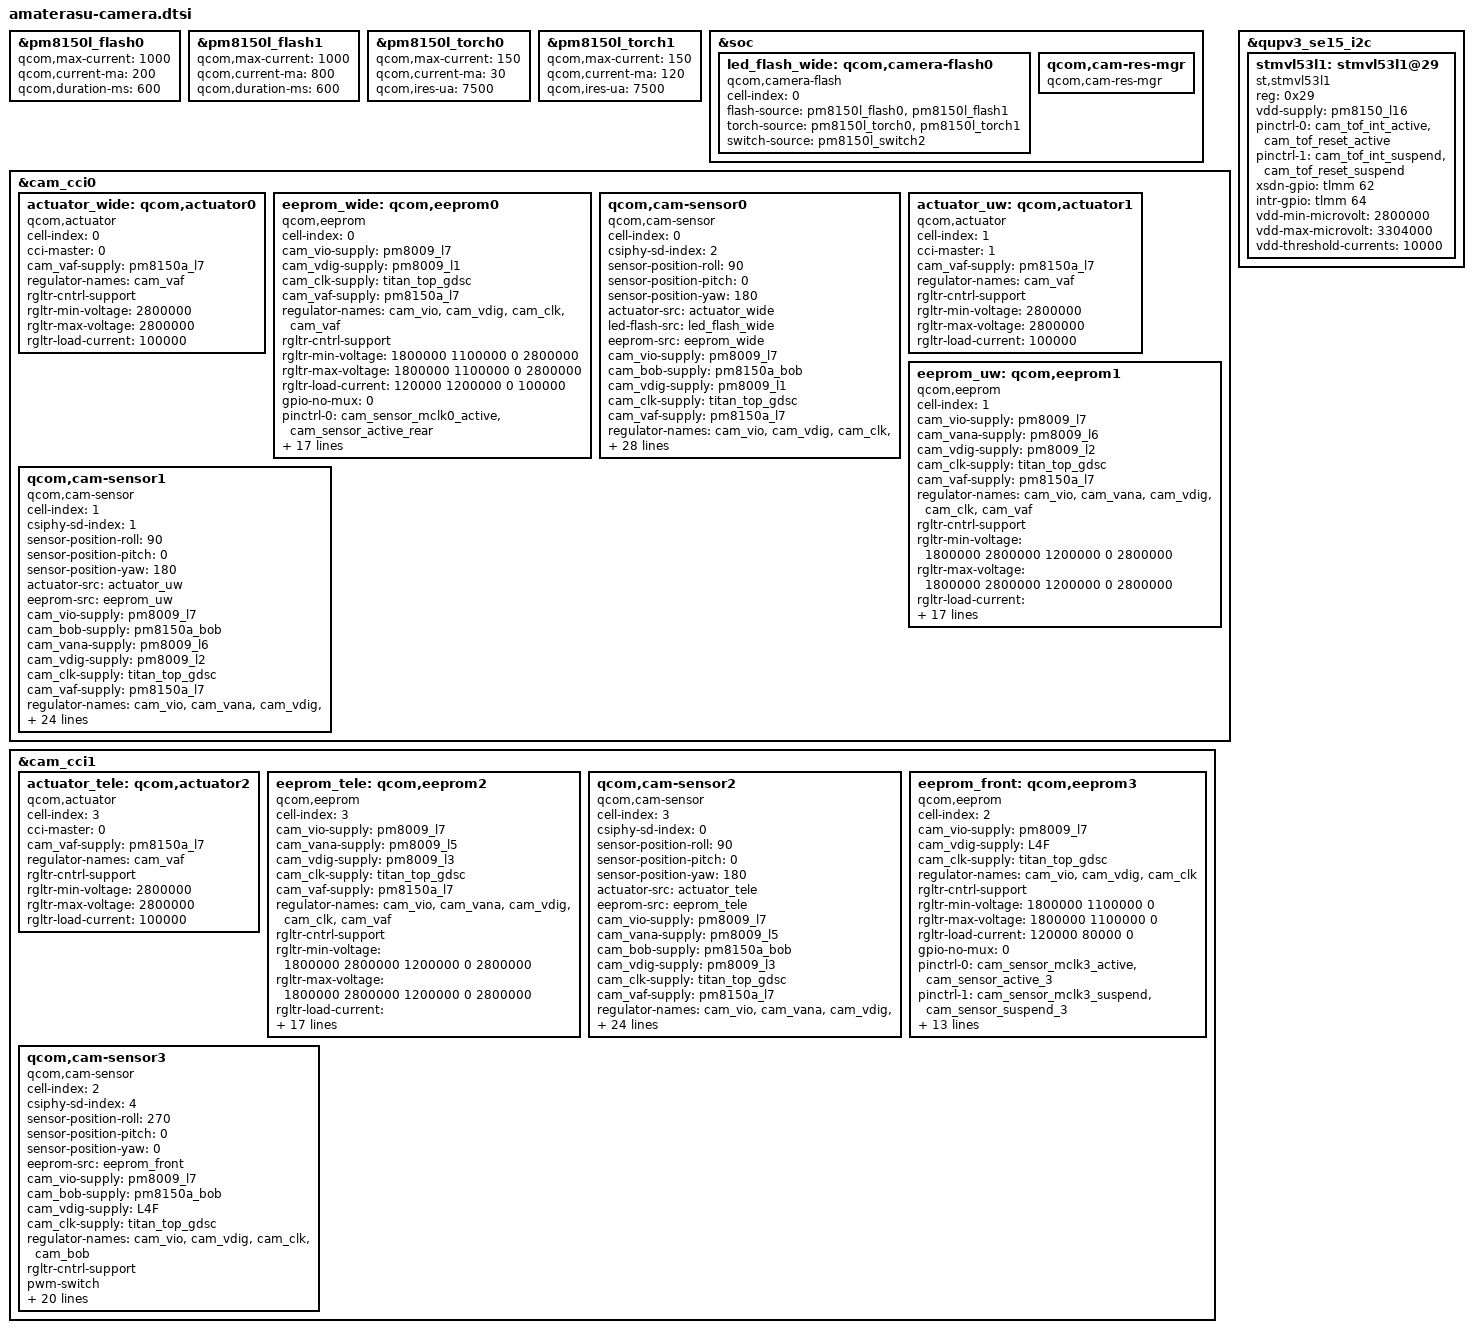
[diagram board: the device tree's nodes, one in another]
/*
 * FCNT arrows 5G (F-51A) - Camera: CCI sensors/actuators/EEPROMs, flash LEDs, resource manager and VL53L1 ToF.
 *
 * Reconstructed from the FCNT stock dtbo (kona FFRD REV7 SKU3); FFRD is
 * derived from the CLO kona QRD board files.
 */

&pm8150l_flash0 {
	qcom,max-current = <1000>;
	qcom,current-ma = <200>;
	qcom,duration-ms = <600>;
};

&pm8150l_flash1 {
	qcom,max-current = <1000>;
	qcom,current-ma = <800>;
	qcom,duration-ms = <600>;
};

&pm8150l_torch0 {
	qcom,max-current = <150>;
	qcom,current-ma = <30>;
	qcom,ires-ua = <7500>;
};

&pm8150l_torch1 {
	qcom,max-current = <150>;
	qcom,current-ma = <120>;
	qcom,ires-ua = <7500>;
};

&soc {
	led_flash_wide: qcom,camera-flash0 {
		cell-index = <0>;
		compatible = "qcom,camera-flash";
		flash-source = <&pm8150l_flash0 &pm8150l_flash1>;
		torch-source = <&pm8150l_torch0 &pm8150l_torch1>;
		switch-source = <&pm8150l_switch2>;
		status = "ok";
	};

	qcom,cam-res-mgr {
		compatible = "qcom,cam-res-mgr";
		status = "ok";
	};
};

&cam_cci0 {
	actuator_wide: qcom,actuator0 {
		cell-index = <0>;
		compatible = "qcom,actuator";
		cci-master = <0>;
		cam_vaf-supply = <&pm8150a_l7>;
		regulator-names = "cam_vaf";
		rgltr-cntrl-support;
		rgltr-min-voltage = <2800000>;
		rgltr-max-voltage = <2800000>;
		rgltr-load-current = <100000>;
	};

	eeprom_wide: qcom,eeprom0 {
		cell-index = <0>;
		compatible = "qcom,eeprom";
		cam_vio-supply = <&pm8009_l7>;
		cam_vdig-supply = <&pm8009_l1>;
		cam_clk-supply = <&titan_top_gdsc>;
		cam_vaf-supply = <&pm8150a_l7>;
		regulator-names = "cam_vio", "cam_vdig", "cam_clk", "cam_vaf";
		rgltr-cntrl-support;
		rgltr-min-voltage = <1800000 1100000 0 2800000>;
		rgltr-max-voltage = <1800000 1100000 0 2800000>;
		rgltr-load-current = <120000 1200000 0 100000>;
		gpio-no-mux = <0>;
		pinctrl-names = "cam_default", "cam_suspend";
		pinctrl-0 = <&cam_sensor_mclk0_active &cam_sensor_active_rear>;
		pinctrl-1 = <&cam_sensor_mclk0_suspend &cam_sensor_suspend_rear>;
		gpios = <&tlmm 94 0 &tlmm 93 0 &pm8009_gpios 2 0 &pm8009_gpios 3 0>;
		gpio-reset = <1>;
		gpio-custom1 = <2>;
		gpio-custom2 = <3>;
		gpio-req-tbl-num = <0 1 2 3>;
		gpio-req-tbl-flags = <0x1 0x0 0x0 0x0>;
		gpio-req-tbl-label = "CAMIF_MCLK0", "CAM_RESET", "CAM_VANA", "CAM_VANA2";
		sensor-position = <0>;
		sensor-mode = <0>;
		cci-master = <0>;
		status = "ok";
		clocks = <&clock_camcc 0x49>;
		clock-names = "cam_clk";
		clock-cntl-level = "turbo";
		clock-rates = <0x16e3600>;
	};

	qcom,cam-sensor0 {
		cell-index = <0>;
		compatible = "qcom,cam-sensor";
		csiphy-sd-index = <2>;
		sensor-position-roll = <90>;
		sensor-position-pitch = <0>;
		sensor-position-yaw = <180>;
		actuator-src = <&actuator_wide>;
		led-flash-src = <&led_flash_wide>;
		eeprom-src = <&eeprom_wide>;
		cam_vio-supply = <&pm8009_l7>;
		cam_bob-supply = <&pm8150a_bob>;
		cam_vdig-supply = <&pm8009_l1>;
		cam_clk-supply = <&titan_top_gdsc>;
		cam_vaf-supply = <&pm8150a_l7>;
		regulator-names = "cam_vio", "cam_vdig", "cam_clk", "cam_bob", "cam_vaf";
		rgltr-cntrl-support;
		pwm-switch;
		rgltr-min-voltage = <1800000 1100000 0 3008000 2800000>;
		rgltr-max-voltage = <1800000 1100000 0 3960000 2800000>;
		rgltr-load-current = <120000 1200000 0 2000000 100000>;
		gpio-no-mux = <0>;
		pinctrl-names = "cam_default", "cam_suspend";
		pinctrl-0 = <&cam_sensor_mclk0_active &cam_sensor_active_rear>;
		pinctrl-1 = <&cam_sensor_mclk0_suspend &cam_sensor_suspend_rear>;
		gpios = <&tlmm 94 0 &tlmm 93 0 &pm8009_gpios 2 0 &pm8009_gpios 3 0>;
		gpio-reset = <1>;
		gpio-custom1 = <2>;
		gpio-custom2 = <3>;
		gpio-req-tbl-num = <0 1 2 3>;
		gpio-req-tbl-flags = <0x1 0x0 0x0 0x0>;
		gpio-req-tbl-label = "CAMIF_MCLK0", "CAM_RESET", "CAM_VANA", "CAM_VANA2";
		sensor-mode = <0>;
		cci-master = <0>;
		status = "ok";
		clocks = <&clock_camcc 0x49>;
		clock-names = "cam_clk";
		clock-cntl-level = "turbo";
		clock-rates = <0x16e3600>;
	};

	actuator_uw: qcom,actuator1 {
		cell-index = <1>;
		compatible = "qcom,actuator";
		cci-master = <1>;
		cam_vaf-supply = <&pm8150a_l7>;
		regulator-names = "cam_vaf";
		rgltr-cntrl-support;
		rgltr-min-voltage = <2800000>;
		rgltr-max-voltage = <2800000>;
		rgltr-load-current = <100000>;
	};

	eeprom_uw: qcom,eeprom1 {
		cell-index = <1>;
		compatible = "qcom,eeprom";
		cam_vio-supply = <&pm8009_l7>;
		cam_vana-supply = <&pm8009_l6>;
		cam_vdig-supply = <&pm8009_l2>;
		cam_clk-supply = <&titan_top_gdsc>;
		cam_vaf-supply = <&pm8150a_l7>;
		regulator-names = "cam_vio", "cam_vana", "cam_vdig", "cam_clk", "cam_vaf";
		rgltr-cntrl-support;
		rgltr-min-voltage = <1800000 2800000 1200000 0 2800000>;
		rgltr-max-voltage = <1800000 2800000 1200000 0 2800000>;
		rgltr-load-current = <120000 80000 1200000 0 100000>;
		gpio-no-mux = <0>;
		pinctrl-names = "cam_default", "cam_suspend";
		pinctrl-0 = <&cam_sensor_mclk1_active &cam_sensor_active_rear_aux>;
		pinctrl-1 = <&cam_sensor_mclk1_suspend &cam_sensor_suspend_rear_aux>;
		gpios = <&tlmm 95 0 &tlmm 92 0>;
		gpio-reset = <1>;
		gpio-req-tbl-num = <0 1>;
		gpio-req-tbl-flags = <0x1 0x0>;
		gpio-req-tbl-label = "CAMIF_MCLK1", "CAM_RESET";
		sensor-position = <0>;
		sensor-mode = <0>;
		cci-master = <1>;
		status = "ok";
		clocks = <&clock_camcc 0x4b>;
		clock-names = "cam_clk";
		clock-cntl-level = "turbo";
		clock-rates = <0x16e3600>;
	};

	qcom,cam-sensor1 {
		cell-index = <1>;
		compatible = "qcom,cam-sensor";
		csiphy-sd-index = <1>;
		sensor-position-roll = <90>;
		sensor-position-pitch = <0>;
		sensor-position-yaw = <180>;
		actuator-src = <&actuator_uw>;
		eeprom-src = <&eeprom_uw>;
		cam_vio-supply = <&pm8009_l7>;
		cam_bob-supply = <&pm8150a_bob>;
		cam_vana-supply = <&pm8009_l6>;
		cam_vdig-supply = <&pm8009_l2>;
		cam_clk-supply = <&titan_top_gdsc>;
		cam_vaf-supply = <&pm8150a_l7>;
		regulator-names = "cam_vio", "cam_vana", "cam_vdig", "cam_clk", "cam_bob", "cam_vaf";
		rgltr-cntrl-support;
		pwm-switch;
		rgltr-min-voltage = <1800000 2800000 1200000 0 3008000 2800000>;
		rgltr-max-voltage = <1800000 2800000 1200000 0 3960000 2800000>;
		rgltr-load-current = <120000 80000 1200000 0 2000000 100000>;
		gpio-no-mux = <0>;
		pinctrl-names = "cam_default", "cam_suspend";
		pinctrl-0 = <&cam_sensor_mclk1_active &cam_sensor_active_rear_aux>;
		pinctrl-1 = <&cam_sensor_mclk1_suspend &cam_sensor_suspend_rear_aux>;
		gpios = <&tlmm 95 0 &tlmm 92 0>;
		gpio-reset = <1>;
		gpio-req-tbl-num = <0 1>;
		gpio-req-tbl-flags = <0x1 0x0>;
		gpio-req-tbl-label = "CAMIF_MCLK1", "CAM_RESET";
		sensor-mode = <0>;
		cci-master = <1>;
		status = "ok";
		clocks = <&clock_camcc 0x4b>;
		clock-names = "cam_clk";
		clock-cntl-level = "turbo";
		clock-rates = <0x16e3600>;
	};
};

&cam_cci1 {
	actuator_tele: qcom,actuator2 {
		cell-index = <3>;
		compatible = "qcom,actuator";
		cci-master = <0>;
		cam_vaf-supply = <&pm8150a_l7>;
		regulator-names = "cam_vaf";
		rgltr-cntrl-support;
		rgltr-min-voltage = <2800000>;
		rgltr-max-voltage = <2800000>;
		rgltr-load-current = <100000>;
	};

	eeprom_tele: qcom,eeprom2 {
		cell-index = <3>;
		compatible = "qcom,eeprom";
		cam_vio-supply = <&pm8009_l7>;
		cam_vana-supply = <&pm8009_l5>;
		cam_vdig-supply = <&pm8009_l3>;
		cam_clk-supply = <&titan_top_gdsc>;
		cam_vaf-supply = <&pm8150a_l7>;
		regulator-names = "cam_vio", "cam_vana", "cam_vdig", "cam_clk", "cam_vaf";
		rgltr-cntrl-support;
		rgltr-min-voltage = <1800000 2800000 1200000 0 2800000>;
		rgltr-max-voltage = <1800000 2800000 1200000 0 2800000>;
		rgltr-load-current = <120000 80000 1200000 0 100000>;
		gpio-no-mux = <0>;
		pinctrl-names = "cam_default", "cam_suspend";
		pinctrl-0 = <&cam_sensor_mclk2_active &cam_sensor_active_rst2>;
		pinctrl-1 = <&cam_sensor_mclk2_suspend &cam_sensor_suspend_rst2>;
		gpios = <&tlmm 96 0 &tlmm 78 0>;
		gpio-reset = <1>;
		gpio-req-tbl-num = <0 1>;
		gpio-req-tbl-flags = <0x1 0x0>;
		gpio-req-tbl-label = "CAMIF_MCLK2", "CAM_RESET";
		sensor-position = <0>;
		sensor-mode = <0>;
		cci-master = <0>;
		status = "ok";
		clocks = <&clock_camcc 0x4d>;
		clock-names = "cam_clk";
		clock-cntl-level = "turbo";
		clock-rates = <0x16e3600>;
	};

	qcom,cam-sensor2 {
		cell-index = <3>;
		compatible = "qcom,cam-sensor";
		csiphy-sd-index = <0>;
		sensor-position-roll = <90>;
		sensor-position-pitch = <0>;
		sensor-position-yaw = <180>;
		actuator-src = <&actuator_tele>;
		eeprom-src = <&eeprom_tele>;
		cam_vio-supply = <&pm8009_l7>;
		cam_vana-supply = <&pm8009_l5>;
		cam_bob-supply = <&pm8150a_bob>;
		cam_vdig-supply = <&pm8009_l3>;
		cam_clk-supply = <&titan_top_gdsc>;
		cam_vaf-supply = <&pm8150a_l7>;
		regulator-names = "cam_vio", "cam_vana", "cam_vdig", "cam_clk", "cam_bob", "cam_vaf";
		rgltr-cntrl-support;
		pwm-switch;
		rgltr-min-voltage = <1800000 2800000 1200000 0 3008000 2800000>;
		rgltr-max-voltage = <1800000 2800000 1200000 0 3960000 2800000>;
		rgltr-load-current = <120000 80000 1200000 0 2000000 100000>;
		gpio-no-mux = <0>;
		pinctrl-names = "cam_default", "cam_suspend";
		pinctrl-0 = <&cam_sensor_mclk2_active &cam_sensor_active_rst2>;
		pinctrl-1 = <&cam_sensor_mclk2_suspend &cam_sensor_suspend_rst2>;
		gpios = <&tlmm 96 0 &tlmm 78 0>;
		gpio-reset = <1>;
		gpio-req-tbl-num = <0 1>;
		gpio-req-tbl-flags = <0x1 0x0>;
		gpio-req-tbl-label = "CAMIF_MCLK2", "CAM_RESET";
		sensor-mode = <0>;
		cci-master = <0>;
		status = "ok";
		clocks = <&clock_camcc 0x4d>;
		clock-names = "cam_clk";
		clock-cntl-level = "turbo";
		clock-rates = <0x16e3600>;
	};

	eeprom_front: qcom,eeprom3 {
		cell-index = <2>;
		compatible = "qcom,eeprom";
		cam_vio-supply = <&pm8009_l7>;
		cam_vdig-supply = <&L4F>;
		cam_clk-supply = <&titan_top_gdsc>;
		regulator-names = "cam_vio", "cam_vdig", "cam_clk";
		rgltr-cntrl-support;
		rgltr-min-voltage = <1800000 1100000 0>;
		rgltr-max-voltage = <1800000 1100000 0>;
		rgltr-load-current = <120000 80000 0>;
		gpio-no-mux = <0>;
		pinctrl-names = "cam_default", "cam_suspend";
		pinctrl-0 = <&cam_sensor_mclk3_active &cam_sensor_active_3>;
		pinctrl-1 = <&cam_sensor_mclk3_suspend &cam_sensor_suspend_3>;
		gpios = <&tlmm 97 0 &tlmm 109 0 &pm8009_gpios 4 0>;
		gpio-reset = <1>;
		gpio-custom1 = <2>;
		gpio-req-tbl-num = <0 1 2>;
		gpio-req-tbl-flags = <0x1 0x0 0x0>;
		gpio-req-tbl-label = "CAMIF_MCLK3", "CAM_RESET", "CAM_VANA";
		sensor-position = <1>;
		sensor-mode = <0>;
		cci-master = <1>;
		status = "ok";
		clocks = <&clock_camcc 0x4f>;
		clock-names = "cam_clk";
		clock-cntl-level = "turbo";
		clock-rates = <0x16e3600>;
	};

	qcom,cam-sensor3 {
		cell-index = <2>;
		compatible = "qcom,cam-sensor";
		csiphy-sd-index = <4>;
		sensor-position-roll = <270>;
		sensor-position-pitch = <0>;
		sensor-position-yaw = <0>;
		eeprom-src = <&eeprom_front>;
		cam_vio-supply = <&pm8009_l7>;
		cam_bob-supply = <&pm8150a_bob>;
		cam_vdig-supply = <&L4F>;
		cam_clk-supply = <&titan_top_gdsc>;
		regulator-names = "cam_vio", "cam_vdig", "cam_clk", "cam_bob";
		rgltr-cntrl-support;
		pwm-switch;
		rgltr-min-voltage = <1800000 1100000 0 3008000>;
		rgltr-max-voltage = <1800000 1100000 0 3960000>;
		rgltr-load-current = <120000 80000 0 2000000>;
		gpio-no-mux = <0>;
		pinctrl-names = "cam_default", "cam_suspend";
		pinctrl-0 = <&cam_sensor_mclk3_active &cam_sensor_active_3>;
		pinctrl-1 = <&cam_sensor_mclk3_suspend &cam_sensor_suspend_3>;
		gpios = <&tlmm 97 0 &tlmm 109 0 &pm8009_gpios 4 0>;
		gpio-reset = <1>;
		gpio-custom1 = <2>;
		gpio-req-tbl-num = <0 1 2>;
		gpio-req-tbl-flags = <0x1 0x0 0x0>;
		gpio-req-tbl-label = "CAMIF_MCLK3", "CAM_RESET", "CAM_VANA";
		sensor-mode = <0>;
		cci-master = <1>;
		status = "ok";
		clocks = <&clock_camcc 0x4f>;
		clock-names = "cam_clk";
		clock-cntl-level = "turbo";
		clock-rates = <0x16e3600>;
	};
};

&qupv3_se15_i2c {
	stmvl53l1: stmvl53l1@29 {
		compatible = "st,stmvl53l1";
		reg = <0x29>;
		vdd-supply = <&pm8150_l16>;
		pinctrl-names = "cam_default", "cam_suspend";
		pinctrl-0 = <&cam_tof_int_active &cam_tof_reset_active>;
		pinctrl-1 = <&cam_tof_int_suspend &cam_tof_reset_suspend>;
		xsdn-gpio = <&tlmm 62 0>;
		intr-gpio = <&tlmm 64 0>;
		vdd-min-microvolt = <2800000>;
		vdd-max-microvolt = <3304000>;
		vdd-threshold-currents = <10000>;
	};
};
